# C66_COREPAC_C66_RATCFG register map
Vendor: Texas Instruments
Peripheral module from a debugger description file (folder J7ES).
Registers are 32-bit, read-only, reset values left out (the file's numbers can be read two ways) unless marked. A register's access mark holds for its fields unless they carry their own. Offsets are as the file gives them; lines under a group give offsets from that group; [hi:lo] are bit positions; {n}, {i} and the like mark numbered series; 'fields as' and 'values as' point back to an identical list; <NAME> marks a mode.

## C66_COREPAC_C66_RATCFG
0x00 C66_RAT_PID — This register contains the major and minor revisions for the module.
  [31:0] REV — TI internal data. Identifies revision of peripheral.
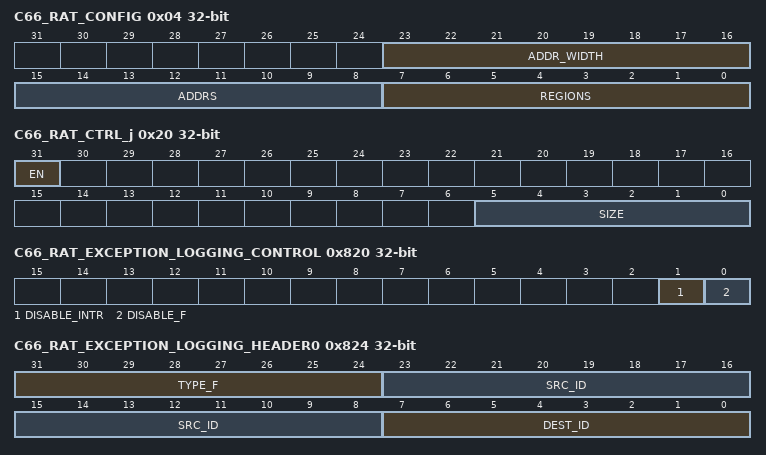
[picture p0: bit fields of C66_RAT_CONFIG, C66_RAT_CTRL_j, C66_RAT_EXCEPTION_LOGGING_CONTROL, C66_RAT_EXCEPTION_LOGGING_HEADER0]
0x04 C66_RAT_CONFIG — This register contains the configuration values for the module.
  [23:16] ADDR_WIDTH — Number of address bits.
  [15:8] ADDRS — Number of addresses.
  [7:0] REGIONS — Number of regions.
0x20 C66_RAT_CTRL_j access per field — This region controls the size and the enable for a region. Offset = 20h + (j * 10h); where j = 0h to Fh.
  [31] EN rw — Enable for the region.
  [5:0] SIZE rw — Size of the region in address bits.
0x24 C66_RAT_BASE_j rw — This register is used for the base address for a region. This is the source address for matching to a region. Offset = 24h + (j * 10h); where j = 0h to Fh.
  [31:0] BASE — Base address for the region. It must be aligned to the programmed size.
0x28 C66_RAT_TRANS_L_j rw — This register contains the translated lower address bits for a region. Offset = 28h + (j * 10h); where j = 0h to Fh.
  [31:0] LOWER — Translated lower address bits for the region. It must be aligned to the programmed size.
0x2C C66_RAT_TRANS_U_j access per field — This register contains the translated upper address bits for a region. Offset = 2Ch + (j * 10h); where j = 0h to Fh
  [15:0] UPPER rw — Translated upper address bits for the region.
0x804 C66_RAT_DESTINATION_ID access per field — This register defines the destination ID value for error messages.
  [7:0] DEST_ID rw — Destination ID.
0x820 C66_RAT_EXCEPTION_LOGGING_CONTROL access per field — This register controls the exception logging.
  [1] DISABLE_INTR rw — Disables logging interrupt when set.
  [0] DISABLE_F rw — Disables logging when set.
0x824 C66_RAT_EXCEPTION_LOGGING_HEADER0 — This register contains the first word of the header.
  [31:24] TYPE_F — Type.
  [23:8] SRC_ID — Source ID.
  [7:0] DEST_ID — Destination ID.
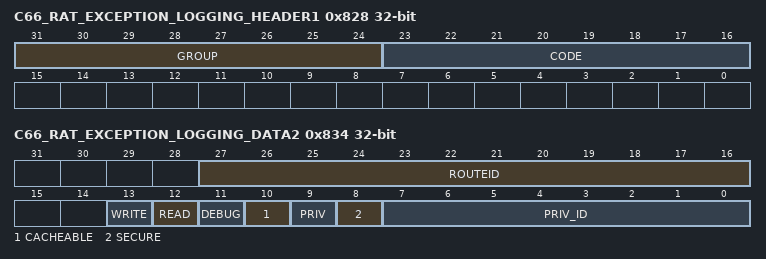
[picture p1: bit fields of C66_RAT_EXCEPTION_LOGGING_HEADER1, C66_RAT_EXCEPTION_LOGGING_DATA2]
0x828 C66_RAT_EXCEPTION_LOGGING_HEADER1 — This register contains the second word of the header.
  [31:24] GROUP, [23:16] CODE
0x82C C66_RAT_EXCEPTION_LOGGING_DATA0 — This register contains the first word of the data.
  [31:0] ADDR_L — Address lower 32 bits.
0x830 C66_RAT_EXCEPTION_LOGGING_DATA1 — This register contains the second word of the data.
  [15:0] ADDR_H — Address upper 12 bits.
0x834 C66_RAT_EXCEPTION_LOGGING_DATA2 — This register contains the third word of the data.
  [27:16] ROUTEID, [13] WRITE, [12] READ, [11] DEBUG, [10] CACHEABLE, [9] PRIV, [8] SECURE, [7:0] PRIV_ID
0x838 C66_RAT_EXCEPTION_LOGGING_DATA3 — This register contains the fourth word of the data. Reading this register will clear the error pending bit.
  [9:0] BYTECNT — Byte count.
0x840 C66_RAT_EXCEPTION_PEND_SET access not given — This register allows to set the exception pending signal.
  [0] PEND_SET — Write a 1 to set the exception pending signal. (access RW1S)
0x844 C66_RAT_EXCEPTION_PEND_CLEAR access not given — This register allows to clear the pend signal.
  [0] PEND_CLR — Write a 1 to clear the exception pending signal. (access RW1C)
0x848 C66_RAT_EXCEPTION_ENABLE_SET access not given — This register allows to set the interrupt enable signal.
  [0] ENABLE_SET — Write a 1 to set the exception interrupt enable signal. (access RW1S)
0x84C C66_RAT_EXCEPTION_ENABLE_CLEAR access not given — This register allows to clear the interrupt enable signal.
  [0] ENABLE_CLR — Write a 1 to clear the exception interrupt enable signal. (access RW1C)
0x850 C66_RAT_EOI_REG access per field — EOI Register The EOI register is used to re-trigger the pulse interrupt signal to ensure that any nested interrupt events are serviced. The software interrupt handler must write to the EOI register at the end of the current interrupt processing routine, so that new events can re-trigger the pulse interrupt signal again. For level interrupt signals the EOI register is not functional and must not be used.
  [15:0] EOI_WR rw — EOI value.
